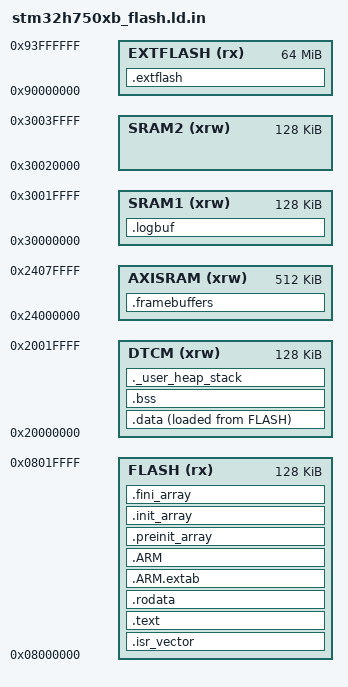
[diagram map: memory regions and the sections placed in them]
/*
** Linker script for STM32H750XBHx — LVGL + QSPI assets
**
** Memory map:
**   FLASH    (128K @ 0x08000000) — startup + core app code
**   EXTFLASH ( 64M @ 0x90000000) — tagged assets + LVGL code/rodata
**   DTCM     (128K @ 0x20000000) — stack, heap, FreeRTOS TCBs, .data
**   AXISRAM  (512K @ 0x24000000) — framebuffers (DMA-accessible)
**
** QSPI_MemoryMapped_Init() runs from internal flash before any .extflash asset
** is accessed.
**
** Flashing:
**   Internal flash only:
**     STM32_Programmer_CLI -c port=SWD -w firmware.elf -v -rst
**   With .extflash assets in external flash (needs external loader):
**     STM32_Programmer_CLI -c port=SWD \
**       -el MT25TL01G_STM32H750B-DISCO.stldr \
**       -w firmware.elf -v -rst
*/

ENTRY(Reset_Handler)

_estack = ORIGIN(DTCM) + LENGTH(DTCM);
_Min_Heap_Size  = 0x2000;
_Min_Stack_Size = 0x2000;

MEMORY
{
  FLASH    (rx)  : ORIGIN = 0x08000000, LENGTH = 128K
  EXTFLASH (rx)  : ORIGIN = 0x90000000, LENGTH = 64M
  DTCM     (xrw) : ORIGIN = 0x20000000, LENGTH = 128K
  AXISRAM  (xrw) : ORIGIN = 0x24000000, LENGTH = 512K
  SRAM1    (xrw) : ORIGIN = 0x30000000, LENGTH = 128K
  SRAM2    (xrw) : ORIGIN = 0x30020000, LENGTH = 128K
}

SECTIONS
{
  .isr_vector :
  {
    . = ALIGN(4);
    KEEP(*(.isr_vector))
    . = ALIGN(4);
  } >FLASH

  /* Code in FLASH (exclude LVGL archive code; it runs from EXTFLASH after QSPI init) */
  .text :
  {
    . = ALIGN(4);
    *(EXCLUDE_FILE(@LVGL_ARCHIVE@) .text)
    *(EXCLUDE_FILE(@LVGL_ARCHIVE@) .text*)
    *(EXCLUDE_FILE(@LVGL_ARCHIVE@) .glue_7)
    *(EXCLUDE_FILE(@LVGL_ARCHIVE@) .glue_7t)
    *(EXCLUDE_FILE(@LVGL_ARCHIVE@) .eh_frame)
    KEEP(*(.init))
    KEEP(*(.fini))
    . = ALIGN(4);
    _etext = .;
  } >FLASH

  /* Read-only data in FLASH: keep LVGL rodata out of internal flash */
  .rodata :
  {
    . = ALIGN(4);
    *(EXCLUDE_FILE(@LVGL_ARCHIVE@) .rodata)
    *(EXCLUDE_FILE(@LVGL_ARCHIVE@) .rodata*)
    . = ALIGN(4);
  } >FLASH

  .ARM.extab :
  {
    . = ALIGN(4);
    *(.ARM.extab* .gnu.linkonce.armextab.*)
    . = ALIGN(4);
  } >FLASH

  .ARM :
  {
    . = ALIGN(4);
    __exidx_start = .;
    *(.ARM.exidx*)
    __exidx_end = .;
    . = ALIGN(4);
  } >FLASH

  .preinit_array :
  {
    . = ALIGN(4);
    PROVIDE_HIDDEN(__preinit_array_start = .);
    KEEP(*(.preinit_array*))
    PROVIDE_HIDDEN(__preinit_array_end = .);
    . = ALIGN(4);
  } >FLASH

  .init_array :
  {
    . = ALIGN(4);
    PROVIDE_HIDDEN(__init_array_start = .);
    KEEP(*(SORT(.init_array.*)))
    KEEP(*(.init_array*))
    PROVIDE_HIDDEN(__init_array_end = .);
    . = ALIGN(4);
  } >FLASH

  .fini_array :
  {
    . = ALIGN(4);
    PROVIDE_HIDDEN(__fini_array_start = .);
    KEEP(*(SORT(.fini_array.*)))
    KEEP(*(.fini_array*))
    PROVIDE_HIDDEN(__fini_array_end = .);
    . = ALIGN(4);
  } >FLASH

  _sidata = LOADADDR(.data);

  .data :
  {
    . = ALIGN(4);
    _sdata = .;
    *(.data)
    *(.data*)
    *(.RamFunc)
    *(.RamFunc*)
    . = ALIGN(4);
    _edata = .;
  } >DTCM AT> FLASH

  . = ALIGN(4);
  .bss :
  {
    _sbss = .;
    __bss_start__ = _sbss;
    *(.bss)
    *(.bss*)
    *(COMMON)
    . = ALIGN(4);
    _ebss = .;
    __bss_end__ = _ebss;
  } >DTCM

  ._user_heap_stack :
  {
    . = ALIGN(8);
    PROVIDE(end = .);
    PROVIDE(_end = .);
    . = . + _Min_Heap_Size;
    . = . + _Min_Stack_Size;
    . = ALIGN(8);
  } >DTCM

  /* LVGL framebuffers in AXI SRAM (DMA-accessible, cache-managed) */
  .framebuffers (NOLOAD) :
  {
    . = ALIGN(32);
    *(.framebuffers)
    *(.framebuffers*)
    . = ALIGN(32);
  } >AXISRAM

  .logbuf (NOLOAD) :
  {
    . = ALIGN(32);
    *(.logbuf)
    *(.logbuf*)
    . = ALIGN(32);
  } >SRAM1

  /* External QSPI flash: tagged assets plus LVGL code/rodata. */
  .extflash :
  {
    . = ALIGN(4);
    *(.extflash)
    *(.extflash*)
    @LVGL_ARCHIVE@:*(.text .text*)
    @LVGL_ARCHIVE@:*(.glue_7 .glue_7t .eh_frame)
    @LVGL_ARCHIVE@:*(.rodata .rodata*)
    . = ALIGN(4);
  } >EXTFLASH

  /DISCARD/ :
  {
    libc.a(*)
    libm.a(*)
    libgcc.a(*)
  }

  .ARM.attributes 0 : { *(.ARM.attributes) }
}
